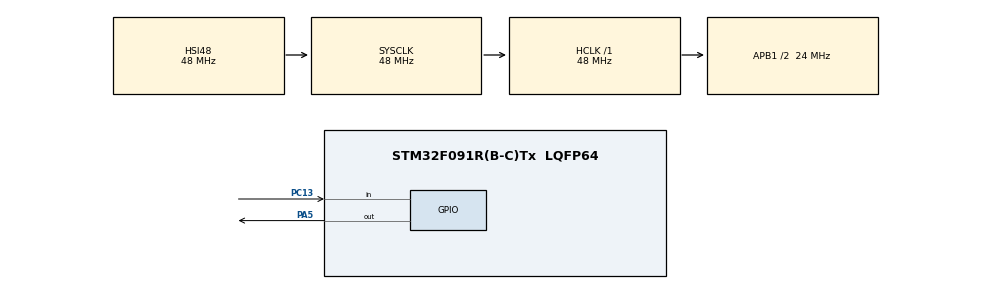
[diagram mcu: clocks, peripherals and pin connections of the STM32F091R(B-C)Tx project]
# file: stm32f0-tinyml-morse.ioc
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Mcu.Family=STM32F0
Mcu.Name=STM32F091R(B-C)Tx
Mcu.Package=LQFP64
NVIC.TIM3_IRQn=true\:0\:0\:false\:false\:true\:true\:true\:true
PA5.Signal=GPIO_Output
PC13.Signal=GPIO_Input
ProjectManager.HeapSize=0x200
ProjectManager.StackSize=0x400
ProjectManager.TargetToolchain=STM32CubeIDE
RCC.AHBFreq_Value=48000000
RCC.APB1CLKDivider=RCC_HCLK_DIV2
RCC.APB1Freq_Value=24000000
RCC.APB1TimFreq_Value=48000000
RCC.HCLKFreq_Value=48000000
RCC.SYSCLKFreq_VALUE=48000000
RCC.SYSCLKSource=RCC_SYSCLKSOURCE_HSI48
STMicroelectronics.X-CUBE-AI.10.2.0.ActivationBufferSizeList=4348
STMicroelectronics.X-CUBE-AI.10.2.0.ActivationBuffers=pool0
STMicroelectronics.X-CUBE-AI.10.2.0.ActivationNames=pool0
STMicroelectronics.X-CUBE-AI.10.2.0.ActivationSizes=AI_MODEL_40HZ_1SEC_DATA_ACTIVATION_1_SIZE
STMicroelectronics.X-CUBE-AI.10.2.0.HeapSize=0x800
STMicroelectronics.X-CUBE-AI.10.2.0.InternalRamActivationBufferMaxSize=AI_MODEL_40HZ_1SEC_DATA_ACTIVATIONS_SIZE
STMicroelectronics.X-CUBE-AI.10.2.0.LatestDirectoryUsed-d75a7c9bb399695504f3fef922215ed6cf31b0299b6d7563f414bbe946e3d4ed=model
STMicroelectronics.X-CUBE-AI.10.2.0.MaximumNumberOfInputLayer=1
STMicroelectronics.X-CUBE-AI.10.2.0.MaximumNumberOfOutputLayer=1
STMicroelectronics.X-CUBE-AI.10.2.0.MaximumSizeOfInputLayer=1
STMicroelectronics.X-CUBE-AI.10.2.0.MaximumSizeOfOutputLayer=1
STMicroelectronics.X-CUBE-AI.10.2.0.ModelActualCompression-d75a7c9bb399695504f3fef922215ed6cf31b0299b6d7563f414bbe946e3d4ed=0.0
STMicroelectronics.X-CUBE-AI.10.2.0.ModelCompression-d75a7c9bb399695504f3fef922215ed6cf31b0299b6d7563f414bbe946e3d4ed=None
STMicroelectronics.X-CUBE-AI.10.2.0.ModelFlashOccupation-d75a7c9bb399695504f3fef922215ed6cf31b0299b6d7563f414bbe946e3d4ed=27024
STMicroelectronics.X-CUBE-AI.10.2.0.ModelHashList=d75a7c9bb399695504f3fef922215ed6cf31b0299b6d7563f414bbe946e3d4ed
STMicroelectronics.X-CUBE-AI.10.2.0.ModelKind-d75a7c9bb399695504f3fef922215ed6cf31b0299b6d7563f414bbe946e3d4ed=TFLITE
STMicroelectronics.X-CUBE-AI.10.2.0.ModelMacc-d75a7c9bb399695504f3fef922215ed6cf31b0299b6d7563f414bbe946e3d4ed=5404
STMicroelectronics.X-CUBE-AI.10.2.0.ModelName-d75a7c9bb399695504f3fef922215ed6cf31b0299b6d7563f414bbe946e3d4ed=model_40hz_1sec
STMicroelectronics.X-CUBE-AI.10.2.0.ModelNameList=model_40hz_1sec
STMicroelectronics.X-CUBE-AI.10.2.0.ModelRamOccupation-d75a7c9bb399695504f3fef922215ed6cf31b0299b6d7563f414bbe946e3d4ed=4348
STMicroelectronics.X-CUBE-AI.10.2.0.ModelStructureFile-d75a7c9bb399695504f3fef922215ed6cf31b0299b6d7563f414bbe946e3d4ed=model\\model_40hz_1sec.tflite
STMicroelectronics.X-CUBE-AI.10.2.0.ModelType-d75a7c9bb399695504f3fef922215ed6cf31b0299b6d7563f414bbe946e3d4ed=STM32Cube.AI MCU runtime
STMicroelectronics.X-CUBE-AI.10.2.0.ReadyForCodeGeneration=true
STMicroelectronics.X-CUBE-AI.10.2.0.StackSize=0x800
STMicroelectronics.X-CUBE-AI.10.2.0.WorkingBufferStartAddrList=0xFFFFFFFF
STMicroelectronics.X-CUBE-AI.10.2.0.XAaCUBEAaAICcArtificialOoIntelligenceJjCore=true
STMicroelectronics.X-CUBE-AI.10.2.0.copyWeightToRam=false
STMicroelectronics.X-CUBE-AI.10.2.0.customLayerConfigEnabled=false
STMicroelectronics.X-CUBE-AI.10.2.0.noOnnxIoTranspose=false
STMicroelectronics.X-CUBE-AI.10.2.0.useInputAllocation=true
STMicroelectronics.X-CUBE-AI.10.2.0.useOutputAllocation=true
TIM3.Period=1000-1
TIM3.Prescaler=48-1
VP_STMicroelectronics.X-CUBE-AI_VS_ArtificialOoIntelligenceJjXAaCUBEAaAI_10.2.0.Mode=ArtificialOoIntelligenceJjXAaCUBEAaAI
VP_TIM3_VS_ClockSourceINT.Mode=Internal
board=custom

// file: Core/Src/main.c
/* USER CODE BEGIN Header */
/**
  ******************************************************************************
  * @file           : main.c
  * @brief          : Main program body
  * @author         : M. Eyub Can, TECH-OHM (https://tech-ohm.com)
  ******************************************************************************
  * @attention
  *
  * Copyright (c) 2025 STMicroelectronics.
  * All rights reserved.
  *
  * This software is licensed under terms that can be found in the LICENSE file
  * in the root directory of this software component.
  * If no LICENSE file comes with this software, it is provided AS-IS.
  *
  ******************************************************************************
  */
/* USER CODE END Header */
#include "main.h"

/* USER CODE BEGIN Includes */
#include <string.h>
#include "model_40hz_1sec.h"
#include "model_40hz_1sec_data.h"
#include "ai_platform.h"
/* USER CODE END Includes */

/* USER CODE BEGIN PTD */
#define SAMPLE_INTERVAL_MS 25
#define SAMPLE_COUNT       40
#define INPUT_LIMIT        30
/* USER CODE END PTD */

/* USER CODE BEGIN PD */
float ai_in[SAMPLE_COUNT];
float ai_out[4];

static ai_handle network = AI_HANDLE_NULL;
/* Activation buffer. Its size comes from the macro X-CUBE-AI generates. */
static uint8_t activations[AI_MODEL_40HZ_1SEC_DATA_ACTIVATIONS_SIZE] __attribute__((aligned(32)));

/* Morse buffers */
static char token[8];
static uint8_t token_len = 0;

static char message[128];
static uint8_t msg_len = 0;
/* USER CODE END PD */

TIM_HandleTypeDef htim3;

/* USER CODE BEGIN PV */
volatile uint32_t ms_counter = 0;
volatile uint8_t  sample_idx = 0;
volatile uint8_t  sampling_done = 0;
volatile int last_class = -1;
/* USER CODE END PV */

void SystemClock_Config(void);
static void MX_GPIO_Init(void);
static void MX_TIM3_Init(void);
/* USER CODE BEGIN PFP */

static void AI_Init(void);
static int  AI_Predict(const float *in40, float *out4);
static int  argmax4(const float *y);

static void push_char(char c);
static void flush_token_to_message(void);
static char morse_to_char(const char *t);

typedef struct { const char *code; char ch; } MorseMap;
static const MorseMap MORSE[] = {
  {".-", 'A'},   {"-...", 'B'}, {"-.-.", 'C'}, {"-..", 'D'},  {".", 'E'},
  {"..-.", 'F'}, {"--.", 'G'},  {"....", 'H'}, {"..", 'I'},   {".---", 'J'},
  {"-.-", 'K'},  {".-..", 'L'}, {"--", 'M'},   {"-.", 'N'},   {"---", 'O'},
  {".--.", 'P'}, {"--.-", 'Q'}, {".-.", 'R'},  {"...", 'S'},  {"-", 'T'},
  {"..-", 'U'},  {"...-", 'V'}, {".--", 'W'},  {"-..-", 'X'}, {"-.--", 'Y'},
  {"--..", 'Z'},
};
/* USER CODE END PFP */

/* USER CODE BEGIN 0 */

static char morse_to_char(const char *t)
{
  for (unsigned i = 0; i < sizeof(MORSE)/sizeof(MORSE[0]); i++)
    if (strcmp(MORSE[i].code, t) == 0) return MORSE[i].ch;
  return '?';
}

static void push_char(char c)
{
  if (msg_len < sizeof(message) - 1)
  {
    message[msg_len++] = c;
    message[msg_len] = '\0';
  }
}

static void flush_token_to_message(void)
{
  if (token_len == 0) return;
  token[token_len] = '\0';
  push_char(morse_to_char(token));
  token_len = 0;
}

static int argmax4(const float *y)
{
  int imax = 0;
  float vmax = y[0];
  for (int i = 1; i < 4; i++)
  {
    if (y[i] > vmax) { vmax = y[i]; imax = i; }
  }
  return imax;
}

static void AI_Init(void)
{
  ai_error err;
  const ai_handle acts[] = { activations };

  err = ai_model_40hz_1sec_create_and_init(&network, acts, NULL);
  if (err.type != AI_ERROR_NONE)
  {
    Error_Handler();
  }
}
static int AI_Predict(const float *in40, float *out4)
{
  ai_i32 n_batch;

  ai_buffer *in  = ai_model_40hz_1sec_inputs_get(network, NULL);
  ai_buffer *out = ai_model_40hz_1sec_outputs_get(network, NULL);
  if (!in || !out) return -1;

  in[0].data  = AI_HANDLE_PTR((void*)in40);
  out[0].data = AI_HANDLE_PTR((void*)out4);

  n_batch = ai_model_40hz_1sec_run(network, in, out);
  return (n_batch == 1) ? 0 : -1;
}

/* TIM3 interrupt callback: 1ms tick, sample every 25ms, 40 samples = 1 second */
void HAL_TIM_PeriodElapsedCallback(TIM_HandleTypeDef *htim)
{
  if (htim->Instance == TIM3)
  {
    ms_counter++;

    if ((ms_counter % SAMPLE_INTERVAL_MS) == 0 && sample_idx < SAMPLE_COUNT)
    {
      /* PC13 active-low button: pressed=1, released=0 */
      uint8_t btn = (HAL_GPIO_ReadPin(GPIOC, GPIO_PIN_13) == GPIO_PIN_RESET) ? 1 : 0;
      ai_in[sample_idx++] = (float)btn;
    }

    if (sample_idx >= SAMPLE_COUNT)
      sampling_done = 1;
  }
}
/* USER CODE END 0 */

int main(void)
{

  /* MCU Configuration--------------------------------------------------------*/

  /* Reset of all peripherals, Initializes the Flash interface and the Systick. */
  HAL_Init();

  /* Configure the system clock */
  SystemClock_Config();

  /* Initialize all configured peripherals */
  MX_GPIO_Init();
  MX_TIM3_Init();
  /* USER CODE BEGIN 2 */
  AI_Init();
  HAL_TIM_Base_Start_IT(&htim3);

  memset(message, 0, sizeof(message));
   memset(token, 0, sizeof(token));

   int input_count = 0;

  /* USER CODE END 2 */

  /* Infinite loop */
  while (1)
  {

    /* USER CODE BEGIN 3 */

	  if (sampling_done)
	      {
	        sampling_done = 0;

	        /* Run AI on last 1-second window (40 samples) */
	        if (AI_Predict(ai_in, ai_out) == 0)
	        {
	          last_class = argmax4(ai_out); /* 0..3 */

	          /* Morse logic:
	             0: dot -> add '.'
	             2: dash -> add '-'
	             3: blank -> letter end
	             1: double click -> word end
	          */
	          if (last_class == 0)
	          {
	            if (token_len < sizeof(token) - 1) token[token_len++] = '.';
	          }
	          else if (last_class == 2)
	          {
	            if (token_len < sizeof(token) - 1) token[token_len++] = '-';
	          }
	          else if (last_class == 3)
	          {
	            flush_token_to_message();
	          }
	          else if (last_class == 1)
	          {
	            flush_token_to_message();
	            push_char(' ');
	          }
	        }

	        /* Prepare next 1-second capture window */
	        ms_counter = 0;
	        sample_idx = 0;

	        input_count++;
	        if (input_count >= INPUT_LIMIT)
	        {
	          /* finish any remaining token */
	          flush_token_to_message();
	          /* Now 'message' is final output (watch in debugger) */
	          while (1) { /* stop here for debugger */ }
	        }
	      }
  }
  /* USER CODE END 3 */
}

void SystemClock_Config(void)
{
  RCC_OscInitTypeDef RCC_OscInitStruct = {0};
  RCC_ClkInitTypeDef RCC_ClkInitStruct = {0};

  /** Initializes the RCC Oscillators according to the specified parameters
  * in the RCC_OscInitTypeDef structure.
  */
  RCC_OscInitStruct.OscillatorType = RCC_OSCILLATORTYPE_HSI48;
  RCC_OscInitStruct.HSI48State = RCC_HSI48_ON;
  RCC_OscInitStruct.PLL.PLLState = RCC_PLL_NONE;
  if (HAL_RCC_OscConfig(&RCC_OscInitStruct) != HAL_OK)
  {
    Error_Handler();
  }

  /** Initializes the CPU, AHB and APB buses clocks
  */
  RCC_ClkInitStruct.ClockType = RCC_CLOCKTYPE_HCLK|RCC_CLOCKTYPE_SYSCLK
                              |RCC_CLOCKTYPE_PCLK1;
  RCC_ClkInitStruct.SYSCLKSource = RCC_SYSCLKSOURCE_HSI48;
  RCC_ClkInitStruct.AHBCLKDivider = RCC_SYSCLK_DIV1;
  RCC_ClkInitStruct.APB1CLKDivider = RCC_HCLK_DIV2;

  if (HAL_RCC_ClockConfig(&RCC_ClkInitStruct, FLASH_LATENCY_1) != HAL_OK)
  {
    Error_Handler();
  }
}

static void MX_TIM3_Init(void)
{

  TIM_ClockConfigTypeDef sClockSourceConfig = {0};
  TIM_MasterConfigTypeDef sMasterConfig = {0};

  htim3.Instance = TIM3;
  htim3.Init.Prescaler = 48-1;
  htim3.Init.CounterMode = TIM_COUNTERMODE_UP;
  htim3.Init.Period = 1000-1;
  htim3.Init.ClockDivision = TIM_CLOCKDIVISION_DIV1;
  htim3.Init.AutoReloadPreload = TIM_AUTORELOAD_PRELOAD_DISABLE;
  if (HAL_TIM_Base_Init(&htim3) != HAL_OK)
  {
    Error_Handler();
  }
  sClockSourceConfig.ClockSource = TIM_CLOCKSOURCE_INTERNAL;
  if (HAL_TIM_ConfigClockSource(&htim3, &sClockSourceConfig) != HAL_OK)
  {
    Error_Handler();
  }
  sMasterConfig.MasterOutputTrigger = TIM_TRGO_RESET;
  sMasterConfig.MasterSlaveMode = TIM_MASTERSLAVEMODE_DISABLE;
  if (HAL_TIMEx_MasterConfigSynchronization(&htim3, &sMasterConfig) != HAL_OK)
  {
    Error_Handler();
  }

}

static void MX_GPIO_Init(void)
{
  GPIO_InitTypeDef GPIO_InitStruct = {0};

  /* GPIO Ports Clock Enable */
  __HAL_RCC_GPIOC_CLK_ENABLE();
  __HAL_RCC_GPIOA_CLK_ENABLE();

  /*Configure GPIO pin Output Level */
  HAL_GPIO_WritePin(GPIOA, GPIO_PIN_5, GPIO_PIN_RESET);

  /*Configure GPIO pin : PC13 */
  GPIO_InitStruct.Pin = GPIO_PIN_13;
  GPIO_InitStruct.Mode = GPIO_MODE_INPUT;
  GPIO_InitStruct.Pull = GPIO_NOPULL;
  HAL_GPIO_Init(GPIOC, &GPIO_InitStruct);

  /*Configure GPIO pin : PA5 */
  GPIO_InitStruct.Pin = GPIO_PIN_5;
  GPIO_InitStruct.Mode = GPIO_MODE_OUTPUT_PP;
  GPIO_InitStruct.Pull = GPIO_NOPULL;
  GPIO_InitStruct.Speed = GPIO_SPEED_FREQ_LOW;
  HAL_GPIO_Init(GPIOA, &GPIO_InitStruct);

}

void Error_Handler(void)
{
  __disable_irq();
  while (1)
  {
  }
}
